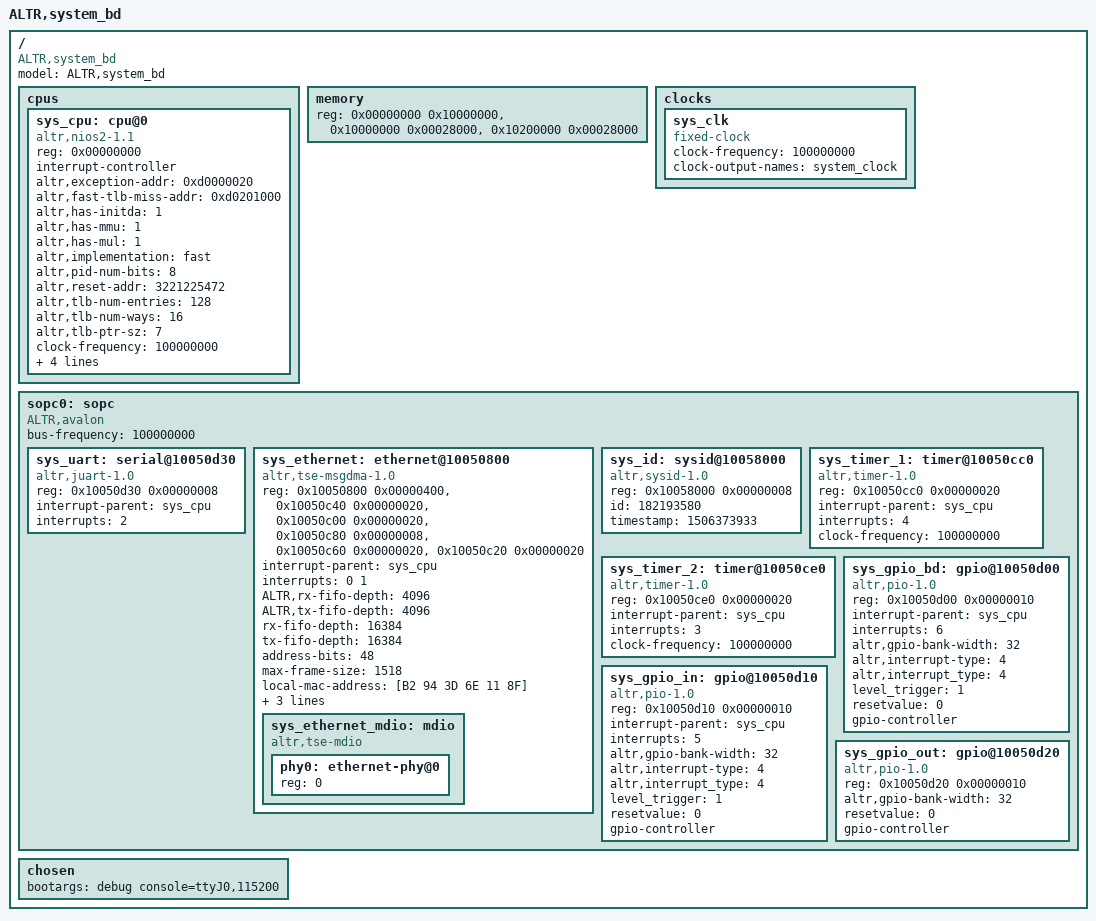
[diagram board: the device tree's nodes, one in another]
// SPDX-License-Identifier: GPL-2.0
/*
 * Complete Radio Card platform containing AD9371
 * Link: https://wiki.analog.com/resources/eval/user-guides/mykonos/quickstart
 *
 * hdl_project: <adrv9371x/a10gx>
 * board_revision: <A>
 *
 * Copyright 2016-2019 Analog Devices Inc.
 */
/dts-v1/;

/ {
	model = "ALTR,system_bd";
	compatible = "ALTR,system_bd";
	#address-cells = <1>;
	#size-cells = <1>;

	cpus {
		#address-cells = <1>;
		#size-cells = <0>;

		sys_cpu: cpu@0 {
			device_type = "cpu";
			compatible = "altr,nios2-1.1";
			reg = <0x00000000>;
			interrupt-controller;
			#interrupt-cells = <1>;
			altr,exception-addr = <0xd0000020>;
			altr,fast-tlb-miss-addr = <0xd0201000>;
			altr,has-initda = <1>;
			altr,has-mmu = <1>;
			altr,has-mul = <1>;
			altr,implementation = "fast";
			altr,pid-num-bits = <8>;
			altr,reset-addr = <3221225472>;
			altr,tlb-num-entries = <128>;
			altr,tlb-num-ways = <16>;
			altr,tlb-ptr-sz = <7>;
			clock-frequency = <100000000>;
			dcache-line-size = <32>;
			dcache-size = <32768>;
			icache-line-size = <32>;
			icache-size = <32768>;
		};
	};

	memory {
		device_type = "memory";
		reg = <0x00000000 0x10000000>,
			  <0x10000000 0x00028000>,
			  <0x10200000 0x00028000>;
	};

	clocks {
		sys_clk: sys_clk {
			#clock-cells = <0>;
			compatible = "fixed-clock";
			clock-frequency = <100000000>;
			clock-output-names = "system_clock";
		};
	};

	sopc0: sopc {
		device_type = "soc";
		ranges;
		#address-cells = <1>;
		#size-cells = <1>;
		compatible = "ALTR,avalon", "simple-bus";
		bus-frequency = <100000000>;

		sys_uart: serial@10050d30 {
			compatible = "altr,juart-1.0";
			reg = <0x10050d30 0x00000008>;
			interrupt-parent = <&sys_cpu>;
			interrupts = <2>;
		};

		sys_ethernet: ethernet@10050800 {
			compatible = "altr,tse-msgdma-1.0", "altr,tse-1.0";
			reg = <0x10050800 0x00000400>,
				  <0x10050c40 0x00000020>,
				  <0x10050c00 0x00000020>,
				  <0x10050c80 0x00000008>,
				  <0x10050c60 0x00000020>,
				  <0x10050c20 0x00000020>;
			reg-names = "control_port", "rx_csr", "rx_desc", "rx_resp", "tx_csr", "tx_desc";
			interrupt-parent = <&sys_cpu>;
			interrupts = <0 1>;
			interrupt-names = "rx_irq", "tx_irq";
			ALTR,rx-fifo-depth = <4096>;
			ALTR,tx-fifo-depth = <4096>;
			rx-fifo-depth = <16384>;
			tx-fifo-depth = <16384>;
			address-bits = <48>;
			max-frame-size = <1518>;
			local-mac-address = [B2 94 3D 6E 11 8F];
			altr,enable-sup-addr = <0>;
			altr,enable-hash = <0>;
			phy-mode = "sgmii";

			sys_ethernet_mdio: mdio {
				compatible = "altr,tse-mdio";
				#address-cells = <1>;
				#size-cells = <0>;
				phy0: ethernet-phy@0 {
					reg = <0>;
					device_type = "ethernet-phy";
				};
			};
		};

		sys_id: sysid@10058000 {
			compatible = "altr,sysid-1.0";
			reg = <0x10058000 0x00000008>;
			id = <182193580>;
			timestamp = <1506373933>;
		};

		sys_timer_1: timer@10050cc0 {
			compatible = "altr,timer-1.0";
			reg = <0x10050cc0 0x00000020>;
			interrupt-parent = <&sys_cpu>;
			interrupts = <4>;
			clock-frequency = <100000000>;
		};

		sys_timer_2: timer@10050ce0 {
			compatible = "altr,timer-1.0";
			reg = <0x10050ce0 0x00000020>;
			interrupt-parent = <&sys_cpu>;
			interrupts = <3>;
			clock-frequency = <100000000>;
		};

		sys_gpio_bd: gpio@10050d00 {
			compatible = "altr,pio-1.0";
			reg = <0x10050d00 0x00000010>;
			interrupt-parent = <&sys_cpu>;
			interrupts = <6>;
			altr,gpio-bank-width = <32>;
			altr,interrupt-type = <4>;
			altr,interrupt_type = <4>;
			level_trigger = <1>;
			resetvalue = <0>;
			#gpio-cells = <2>;
			gpio-controller;
		};

		sys_gpio_in: gpio@10050d10 {
			compatible = "altr,pio-1.0";
			reg = <0x10050d10 0x00000010>;
			interrupt-parent = <&sys_cpu>;
			interrupts = <5>;
			altr,gpio-bank-width = <32>;
			altr,interrupt-type = <4>;
			altr,interrupt_type = <4>;
			level_trigger = <1>;
			resetvalue = <0>;
			#gpio-cells = <2>;
			gpio-controller;
		};

		sys_gpio_out: gpio@10050d20 {
			compatible = "altr,pio-1.0";
			reg = <0x10050d20 0x00000010>;
			altr,gpio-bank-width = <32>;
			resetvalue = <0>;
			#gpio-cells = <2>;
			gpio-controller;
		};
    };
    
    chosen {
		bootargs = "debug console=ttyJ0,115200";
	};
};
